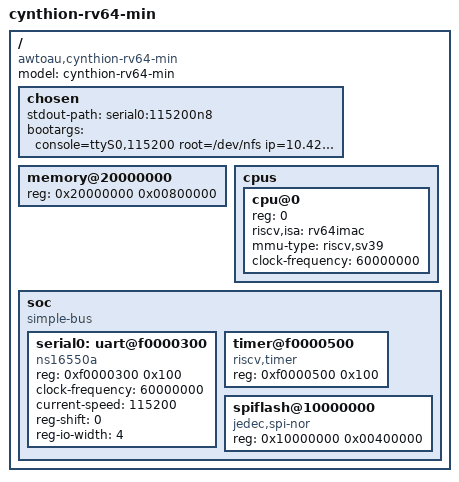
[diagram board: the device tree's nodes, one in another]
/dts-v1/;

/ {
    model = "cynthion-rv64-min";
    compatible = "awtoau,cynthion-rv64-min";

    #address-cells = <1>;
    #size-cells = <1>;

    chosen {
        stdout-path = "serial0:115200n8";
        bootargs = "console=ttyS0,115200 root=/dev/nfs ip=10.42.0.2::10.42.0.1:255.255.255.0::usb0:off rw";
    };

    memory@20000000 {
        device_type = "memory";
        reg = <0x20000000 0x00800000>;
    };

    cpus {
        #address-cells = <1>;
        #size-cells = <0>;

        cpu@0 {
            device_type = "cpu";
            reg = <0>;
            status = "okay";
            riscv,isa = "rv64imac";
            mmu-type = "riscv,sv39";
            clock-frequency = <60000000>;
        };
    };

    soc {
        compatible = "simple-bus";
        #address-cells = <1>;
        #size-cells = <1>;
        ranges;

        serial0: uart@f0000300 {
            compatible = "ns16550a";
            reg = <0xf0000300 0x100>;
            clock-frequency = <60000000>;
            current-speed = <115200>;
            reg-shift = <0>;
            reg-io-width = <4>;
            status = "okay";
        };

        timer@f0000500 {
            compatible = "riscv,timer";
            reg = <0xf0000500 0x100>;
            status = "okay";
        };

        spiflash@10000000 {
            compatible = "jedec,spi-nor";
            reg = <0x10000000 0x00400000>;
            status = "okay";
        };
    };
};
